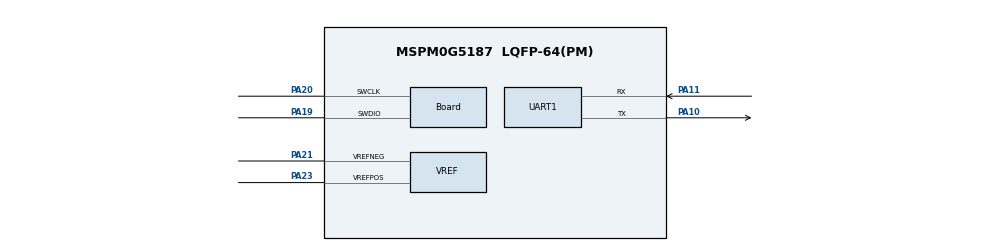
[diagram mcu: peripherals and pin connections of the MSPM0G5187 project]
//@cliArgs --device "MSPM0G518X" --package "LQFP-64(PM)" --part "Default"
//@v2CliArgs --device "MSPM0G5187" --package "LQFP-64(PM)"
// @cliArgs --board /ti/boards/LP_MSPM0G5187 --rtos nortos

/**
 * Import the modules used in this configuration.
 */
const ADC12         = scripting.addModule("/ti/driverlib/ADC12", {}, false);
const ADC121        = ADC12.addInstance();
const Board         = scripting.addModule("/ti/driverlib/Board");
const DMA           = scripting.addModule("/ti/driverlib/DMA");
const SYSCTL        = scripting.addModule("/ti/driverlib/SYSCTL");
const UART          = scripting.addModule("/ti/driverlib/UART", {}, false);
const UART1         = UART.addInstance();
const VREF          = scripting.addModule("/ti/driverlib/VREF");
const ProjectConfig = scripting.addModule("/ti/project_config/ProjectConfig");

/**
 * Write custom configuration values to the imported modules.
 */
const divider7       = system.clockTree["PLL_PDIV"];
divider7.divideValue = 2;

const divider9       = system.clockTree["UDIV"];
divider9.divideValue = 2;

const multiplier2         = system.clockTree["PLL_QDIV"];
multiplier2.multiplyValue = 5;

const mux7       = system.clockTree["HSCLKMUX"];
mux7.inputSelect = "HSCLKMUX_SYSPLL2X";

ADC121.$name                      = "ADC12_0";
ADC121.sampClkDiv                 = "DL_ADC12_CLOCK_DIVIDE_8";
ADC121.repeatMode                 = true;
ADC121.enabledInterrupts          = ["DL_ADC12_INTERRUPT_MEM0_RESULT_LOADED"];
ADC121.sampCnt                    = 1;
ADC121.enabledDMATriggers         = ["DL_ADC12_DMA_MEM0_RESULT_LOADED"];
ADC121.sampleTime0                = "198 us";
ADC121.adcMem0chansel             = "DL_ADC12_INPUT_CHAN_5";
ADC121.adcMem0vrefm               = "VREFM";
ADC121.peripheral.$assign         = "ADC0";
ADC121.peripheral.adcPin5.$assign = "PB24";

Board.peripheral.$assign          = "DEBUGSS";
Board.peripheral.swclkPin.$assign = "PA20";
Board.peripheral.swdioPin.$assign = "PA19";

SYSCTL.MFPCLKEn              = true;
SYSCTL.HFCLKMonitor          = true;
SYSCTL.SYSPLLSource          = "HFCLK";
SYSCTL.SYSPLL_Pdiv           = 1;
SYSCTL.SYSPLL_Qdiv           = 4;
SYSCTL.HFCLKSource           = "HFXT";
SYSCTL.HFCLK_Freq            = 40000000;
SYSCTL.useHFCLK_Manual       = true;
SYSCTL.SYSPLL_CLK2XEn        = true;
SYSCTL.SYSPLL_CLK2XDiv       = 3;
SYSCTL.forceDefaultClkConfig = true;
SYSCTL.clockTreeEn           = true;

UART1.targetBaudRate                      = 115200;
UART1.enabledDMATXTriggers                = "DL_UART_DMA_INTERRUPT_TX";
UART1.enabledDMARXTriggers                = "DL_UART_DMA_INTERRUPT_RX";
UART1.$name                               = "UART_DAP";
UART1.peripheral.$assign                  = "UC0";
UART1.peripheral.rxPin.$assign            = "PA11";
UART1.peripheral.txPin.$assign            = "PA10";
UART1.DMA_CHANNEL_TX.$name                = "DMA_CH1";
UART1.DMA_CHANNEL_TX.addressMode          = "b2f";
UART1.DMA_CHANNEL_TX.srcLength            = "BYTE";
UART1.DMA_CHANNEL_TX.dstLength            = "BYTE";
UART1.DMA_CHANNEL_TX.enableInterrupt      = true;
UART1.DMA_CHANNEL_TX.peripheral.$assign   = "DMA_CH1";
UART1.DMA_CHANNEL_RX.$name                = "DMA_CH0";
UART1.DMA_CHANNEL_RX.addressMode          = "f2b";
UART1.DMA_CHANNEL_RX.srcLength            = "BYTE";
UART1.DMA_CHANNEL_RX.dstLength            = "BYTE";
UART1.DMA_CHANNEL_RX.enableEarlyInterrupt = true;
UART1.DMA_CHANNEL_RX.earlyIntThresh       = "64";
UART1.DMA_CHANNEL_RX.peripheral.$assign   = "DMA_CH0";

VREF.basicMode                     = "DL_VREF_ENABLE_ENABLE_DL_VREF_ENABLE_DISABLE";
VREF.basicVrefPins                 = "VREF+-";
VREF.basicExtVolt                  = 3.3;
VREF.peripheral.$assign            = "VREF";
VREF.peripheral.vrefPosPin.$assign = "PA23";
VREF.peripheral.vrefNegPin.$assign = "PA21";

ProjectConfig.migrationCondition = true;
